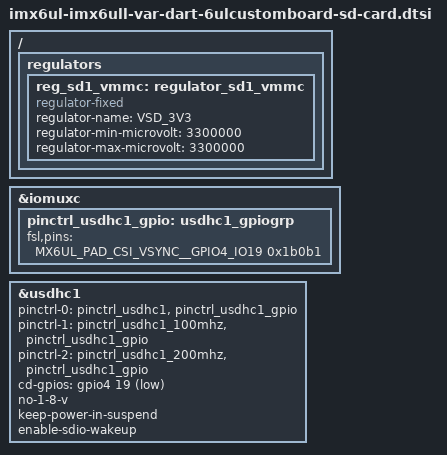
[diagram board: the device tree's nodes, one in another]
/*
 * Copyright (C) 2015-2019 Variscite Ltd. - https://www.variscite.com
 *
 * This program is free software; you can redistribute it and/or modify
 * it under the terms of the GNU General Public License version 2 as
 * published by the Free Software Foundation.
 */

/ {
	regulators {
		reg_sd1_vmmc: regulator_sd1_vmmc {
			compatible = "regulator-fixed";
			regulator-name = "VSD_3V3";
			regulator-min-microvolt = <3300000>;
			regulator-max-microvolt = <3300000>;
		};
	};
};

&iomuxc {
	pinctrl_usdhc1_gpio: usdhc1_gpiogrp {
		fsl,pins = <
			MX6UL_PAD_CSI_VSYNC__GPIO4_IO19		0x1b0b1 /* CD */
		>;
	};
};

&usdhc1 {
	pinctrl-names = "default", "state_100mhz", "state_200mhz";
	pinctrl-0 = <&pinctrl_usdhc1>, <&pinctrl_usdhc1_gpio>;
	pinctrl-1 = <&pinctrl_usdhc1_100mhz>, <&pinctrl_usdhc1_gpio>;
	pinctrl-2 = <&pinctrl_usdhc1_200mhz>, <&pinctrl_usdhc1_gpio>;
	cd-gpios = <&gpio4 19 GPIO_ACTIVE_LOW>;
	no-1-8-v;
	keep-power-in-suspend;
	enable-sdio-wakeup;
	status = "okay";
};
